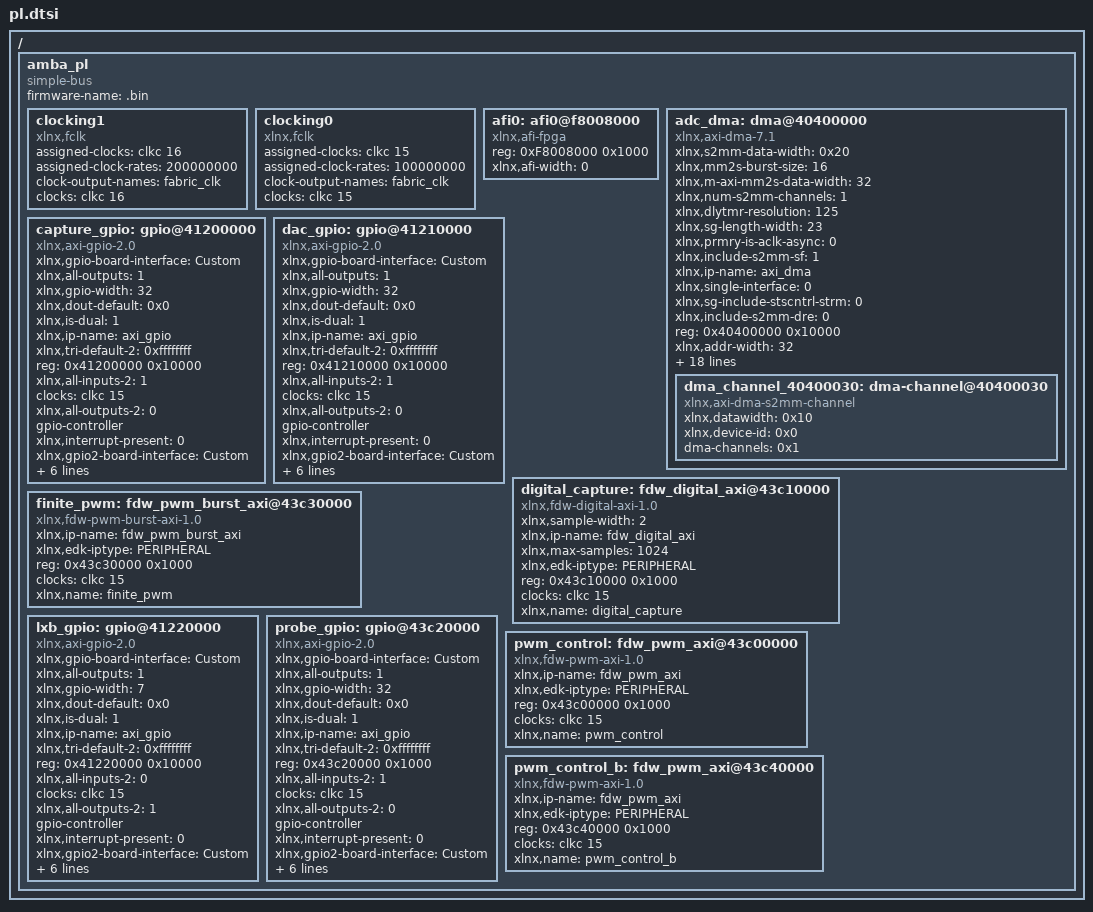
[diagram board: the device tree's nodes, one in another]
/ {
	amba_pl: amba_pl {
		ranges;
		compatible = "simple-bus";
		#address-cells = <1>;
		#size-cells = <1>;
		firmware-name = ".bin";
		clocking1: clocking1 {
			compatible = "xlnx,fclk";
			assigned-clocks = <&clkc 16>;
			assigned-clock-rates = <200000000>;
			#clock-cells = <0>;
			clock-output-names = "fabric_clk";
			clocks = <&clkc 16>;
		};
		clocking0: clocking0 {
			compatible = "xlnx,fclk";
			assigned-clocks = <&clkc 15>;
			assigned-clock-rates = <100000000>;
			#clock-cells = <0>;
			clock-output-names = "fabric_clk";
			clocks = <&clkc 15>;
		};
		afi0: afi0@f8008000 {
			status = "okay";
			compatible = "xlnx,afi-fpga";
			#address-cells = <1>;
			reg = <0xF8008000 0x1000>;
			#size-cells = <0>;
			xlnx,afi-width = <0>;
		};
		adc_dma: dma@40400000 {
			compatible = "xlnx,axi-dma-7.1" , "xlnx,axi-dma-1.00.a";
			xlnx,s2mm-data-width = <0x20>;
			xlnx,mm2s-burst-size = <16>;
			xlnx,m-axi-mm2s-data-width = <32>;
			xlnx,num-s2mm-channels = <1>;
			xlnx,dlytmr-resolution = <125>;
			xlnx,sg-length-width = <23>;
			xlnx,prmry-is-aclk-async = <0>;
			xlnx,include-s2mm-sf = <1>;
			#dma-cells = <1>;
			xlnx,ip-name = "axi_dma";
			xlnx,single-interface = <0>;
			xlnx,sg-include-stscntrl-strm = <0>;
			xlnx,include-s2mm-dre = <0>;
			reg = <0x40400000 0x10000>;
			xlnx,addr-width = <32>;
			xlnx,include-s2mm = <1>;
			clocks = <&clkc 15>, <&clkc 15>;
			xlnx,s-axis-s2mm-tdata-width = <16>;
			xlnx,micro-dma = <0>;
			xlnx,increase-throughput = <0>;
			xlnx,mm2s-data-width = <0x20>;
			xlnx,addrwidth = <0x20>;
			xlnx,sg-use-stsapp-length = <0>;
			xlnx,m-axis-mm2s-tdata-width = <32>;
			xlnx,edk-iptype = "PERIPHERAL";
			xlnx,s2mm-burst-size = <16>;
			xlnx,m-axi-s2mm-data-width = <32>;
			xlnx,num-mm2s-channels = <1>;
			xlnx,enable-multi-channel = <0>;
			status = "okay";
			xlnx,include-mm2s-sf = <1>;
			clock-names = "m_axi_s2mm_aclk" , "s_axi_lite_aclk";
			xlnx,include-mm2s = <0>;
			xlnx,include-mm2s-dre = <0>;
			xlnx,name = "adc_dma";
			dma_channel_40400030: dma-channel@40400030 {
				xlnx,datawidth = <0x10>;
				xlnx,device-id = <0x0>;
				compatible = "xlnx,axi-dma-s2mm-channel";
				dma-channels = <0x1>;
			};
		};
		capture_gpio: gpio@41200000 {
			xlnx,gpio-board-interface = "Custom";
			compatible = "xlnx,axi-gpio-2.0" , "xlnx,xps-gpio-1.00.a";
			xlnx,all-outputs = <1>;
			#gpio-cells = <2>;
			xlnx,gpio-width = <32>;
			xlnx,dout-default = <0x0>;
			xlnx,is-dual = <1>;
			xlnx,ip-name = "axi_gpio";
			xlnx,tri-default-2 = <0xffffffff>;
			reg = <0x41200000 0x10000>;
			xlnx,all-inputs-2 = <1>;
			clocks = <&clkc 15>;
			xlnx,all-outputs-2 = <0>;
			gpio-controller;
			xlnx,interrupt-present = <0>;
			xlnx,gpio2-board-interface = "Custom";
			xlnx,edk-iptype = "PERIPHERAL";
			xlnx,dout-default-2 = <0x0>;
			status = "okay";
			xlnx,gpio2-width = <32>;
			clock-names = "s_axi_aclk";
			xlnx,tri-default = <0xffffffff>;
			xlnx,name = "capture_gpio";
			xlnx,all-inputs = <0>;
		};
		dac_gpio: gpio@41210000 {
			xlnx,gpio-board-interface = "Custom";
			compatible = "xlnx,axi-gpio-2.0" , "xlnx,xps-gpio-1.00.a";
			xlnx,all-outputs = <1>;
			#gpio-cells = <2>;
			xlnx,gpio-width = <32>;
			xlnx,dout-default = <0x0>;
			xlnx,is-dual = <1>;
			xlnx,ip-name = "axi_gpio";
			xlnx,tri-default-2 = <0xffffffff>;
			reg = <0x41210000 0x10000>;
			xlnx,all-inputs-2 = <1>;
			clocks = <&clkc 15>;
			xlnx,all-outputs-2 = <0>;
			gpio-controller;
			xlnx,interrupt-present = <0>;
			xlnx,gpio2-board-interface = "Custom";
			xlnx,edk-iptype = "PERIPHERAL";
			xlnx,dout-default-2 = <0x0>;
			status = "okay";
			xlnx,gpio2-width = <32>;
			clock-names = "s_axi_aclk";
			xlnx,tri-default = <0xffffffff>;
			xlnx,name = "dac_gpio";
			xlnx,all-inputs = <0>;
		};
		digital_capture: fdw_digital_axi@43c10000 {
			compatible = "xlnx,fdw-digital-axi-1.0";
			status = "okay";
			clock-names = "s_axi_aclk";
			xlnx,sample-width = <2>;
			xlnx,ip-name = "fdw_digital_axi";
			xlnx,max-samples = <1024>;
			xlnx,edk-iptype = "PERIPHERAL";
			reg = <0x43c10000 0x1000>;
			clocks = <&clkc 15>;
			xlnx,name = "digital_capture";
		};
		finite_pwm: fdw_pwm_burst_axi@43c30000 {
			compatible = "xlnx,fdw-pwm-burst-axi-1.0";
			status = "okay";
			clock-names = "s_axi_aclk";
			xlnx,ip-name = "fdw_pwm_burst_axi";
			xlnx,edk-iptype = "PERIPHERAL";
			reg = <0x43c30000 0x1000>;
			clocks = <&clkc 15>;
			xlnx,name = "finite_pwm";
		};
		lxb_gpio: gpio@41220000 {
			xlnx,gpio-board-interface = "Custom";
			compatible = "xlnx,axi-gpio-2.0" , "xlnx,xps-gpio-1.00.a";
			xlnx,all-outputs = <1>;
			#gpio-cells = <2>;
			xlnx,gpio-width = <7>;
			xlnx,dout-default = <0x0>;
			xlnx,is-dual = <1>;
			xlnx,ip-name = "axi_gpio";
			xlnx,tri-default-2 = <0xffffffff>;
			reg = <0x41220000 0x10000>;
			xlnx,all-inputs-2 = <0>;
			clocks = <&clkc 15>;
			xlnx,all-outputs-2 = <1>;
			gpio-controller;
			xlnx,interrupt-present = <0>;
			xlnx,gpio2-board-interface = "Custom";
			xlnx,edk-iptype = "PERIPHERAL";
			xlnx,dout-default-2 = <0x0>;
			status = "okay";
			xlnx,gpio2-width = <2>;
			clock-names = "s_axi_aclk";
			xlnx,tri-default = <0xffffffff>;
			xlnx,name = "lxb_gpio";
			xlnx,all-inputs = <0>;
		};
		probe_gpio: gpio@43c20000 {
			xlnx,gpio-board-interface = "Custom";
			compatible = "xlnx,axi-gpio-2.0" , "xlnx,xps-gpio-1.00.a";
			xlnx,all-outputs = <1>;
			#gpio-cells = <2>;
			xlnx,gpio-width = <32>;
			xlnx,dout-default = <0x0>;
			xlnx,is-dual = <1>;
			xlnx,ip-name = "axi_gpio";
			xlnx,tri-default-2 = <0xffffffff>;
			reg = <0x43c20000 0x1000>;
			xlnx,all-inputs-2 = <1>;
			clocks = <&clkc 15>;
			xlnx,all-outputs-2 = <0>;
			gpio-controller;
			xlnx,interrupt-present = <0>;
			xlnx,gpio2-board-interface = "Custom";
			xlnx,edk-iptype = "PERIPHERAL";
			xlnx,dout-default-2 = <0x0>;
			status = "okay";
			xlnx,gpio2-width = <32>;
			clock-names = "s_axi_aclk";
			xlnx,tri-default = <0xffffffff>;
			xlnx,name = "probe_gpio";
			xlnx,all-inputs = <0>;
		};
		pwm_control: fdw_pwm_axi@43c00000 {
			compatible = "xlnx,fdw-pwm-axi-1.0";
			status = "okay";
			clock-names = "s_axi_aclk";
			xlnx,ip-name = "fdw_pwm_axi";
			xlnx,edk-iptype = "PERIPHERAL";
			reg = <0x43c00000 0x1000>;
			clocks = <&clkc 15>;
			xlnx,name = "pwm_control";
		};
		pwm_control_b: fdw_pwm_axi@43c40000 {
			compatible = "xlnx,fdw-pwm-axi-1.0";
			status = "okay";
			clock-names = "s_axi_aclk";
			xlnx,ip-name = "fdw_pwm_axi";
			xlnx,edk-iptype = "PERIPHERAL";
			reg = <0x43c40000 0x1000>;
			clocks = <&clkc 15>;
			xlnx,name = "pwm_control_b";
		};
	};
};
